# ATtiny87 device description
Architecture: AVR8; Family: tinyAVR
Registers are 8-bit, access not given, no defined reset value unless marked. A register's access mark holds for its fields unless they carry their own. Offsets are from the block's base; [hi:lo] are bit positions.

## TC1 (TC16 module) — Timer/Counter, 16-bit
Instances: TC1 0x00
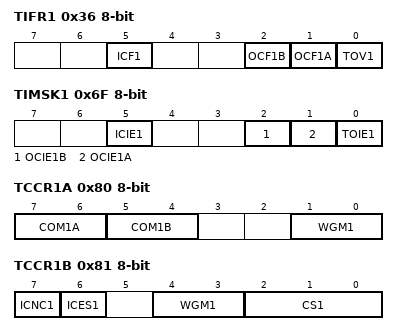
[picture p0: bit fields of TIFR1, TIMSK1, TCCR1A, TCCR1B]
0x36 TIFR1 — Timer/Counter1 Interrupt Flag register
  [5] ICF1 — Timer/Counter1 Input Capture Flag
  [2] OCF1B — Timer/Counter1 Output Compare B Match Flag
  [1] OCF1A — Timer/Counter1 Output Compare A Match Flag
  [0] TOV1 — Timer/Counter1 Overflow Flag
0x6F TIMSK1 — Timer/Counter1 Interrupt Mask Register
  [5] ICIE1 — Timer/Counter1 Input Capture Interrupt Enable
  [2] OCIE1B — Timer/Counter1 Output Compare B Match Interrupt Enable
  [1] OCIE1A — Timer/Counter1 Output Compare A Match Interrupt Enable
  [0] TOIE1 — Timer/Counter1 Overflow Interrupt Enable
0x80 TCCR1A — Timer/Counter1 Control Register A
  [7:6] COM1A — Compare Output Mode 1A, bits
  [5:4] COM1B — Compare Output Mode 1B, bits
  [1:0] WGM1 — Pulse Width Modulator Select Bits
0x81 TCCR1B — Timer/Counter1 Control Register B
  [7] ICNC1 — Input Capture 1 Noise Canceler
  [6] ICES1 — Input Capture 1 Edge Select
  [4:3] WGM1 (bit 2 of the value upward) — Waveform Generation Mode Bits
  [2:0] CS1 — Timer/Counter1 Clock Select bits
    0=NO_CLOCK_SOURCE_STOPPED; 1=RUNNING_NO_PRESCALING; 2=RUNNING_CLK_8; 3=RUNNING_CLK_64; 4=RUNNING_CLK_256; 5=RUNNING_CLK_1024; 6=RUNNING_EXTCLK_TN_FALLING_EDGE; 7=RUNNING_EXTCLK_TN_RISING_EDGE
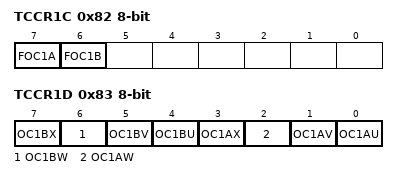
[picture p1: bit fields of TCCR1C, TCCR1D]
0x82 TCCR1C — Timer/Counter1 Control Register C
  [7] FOC1A — Timer/Counter1 Force Output Compare for Channel A
  [6] FOC1B — Timer/Counter1 Force Output Compare for Channel B
0x83 TCCR1D — Timer/Counter1 Control Register D
  [7] OC1BX — Timer/Counter1 Output Compare X-pin Enable for Channel B
  [6] OC1BW — Timer/Counter1 Output Compare W-pin Enable for Channel B
  [5] OC1BV — Timer/Counter1 Output Compare V-pin Enable for Channel B
  [4] OC1BU — Timer/Counter1 Output Compare U-pin Enable for Channel B
  [3] OC1AX — Timer/Counter1 Output Compare X-pin Enable for Channel A
  [2] OC1AW — Timer/Counter1 Output Compare W-pin Enable for Channel A
  [1] OC1AV — Timer/Counter1 Output Compare V-pin Enable for Channel A
  [0] OC1AU — Timer/Counter1 Output Compare U-pin Enable for Channel A
0x84 TCNT1 16-bit — Timer/Counter1 Bytes
0x86 ICR1 16-bit — Timer/Counter1 Input Capture Register Bytes
0x88 OCR1A 16-bit — Timer/Counter1 Output Compare Register A Bytes
0x8A OCR1B 16-bit — Timer/Counter1 Output Compare Register B Bytes

## WDT — Watchdog Timer
Instances: WDT 0x00
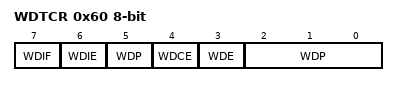
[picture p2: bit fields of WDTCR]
0x60 WDTCR — Watchdog Timer Control Register
  [7] WDIF — Watchdog Timeout Interrupt Flag
  [6] WDIE — Watchdog Timeout Interrupt Enable
  [4] WDCE — Watchdog Change Enable
  [3] WDE — Watch Dog Enable
  [5,2:0] WDP — Watchdog Timer Prescaler Bits
    0=OSCILLATOR_CYCLES_2K; 1=OSCILLATOR_CYCLES_4K; 2=OSCILLATOR_CYCLES_8K; 3=OSCILLATOR_CYCLES_16K; 4=OSCILLATOR_CYCLES_32K; 5=OSCILLATOR_CYCLES_64K; 6=OSCILLATOR_CYCLES_128K; 7=OSCILLATOR_CYCLES_256K; 8=OSCILLATOR_CYCLES_512K; 9=OSCILLATOR_CYCLES_1024K

## EEPROM
Instances: EEPROM 0x00
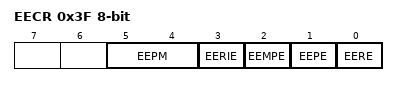
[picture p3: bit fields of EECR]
0x3F EECR — EEPROM Control Register
  [5:4] EEPM — EEPROM Programming Mode Bits
    0=ERASE_AND_WRITE_IN_ONE_OPERATION; 1=ERASE_ONLY; 2=WRITE_ONLY
  [3] EERIE — EEPROM Ready Interrupt Enable
  [2] EEMPE — EEPROM Master Write Enable
  [1] EEPE — EEPROM Write Enable
  [0] EERE — EEPROM Read Enable
0x40 EEDR — EEPROM Data Register
0x41 EEAR 16-bit bits used 8:0 — EEPROM Address Register Bytes

## SPI — Serial Peripheral Interface
Instances: SPI 0x00
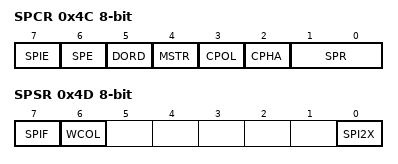
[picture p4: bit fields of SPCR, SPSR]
0x4C SPCR — SPI Control Register
  [7] SPIE — SPI Interrupt Enable
  [6] SPE — SPI Enable
  [5] DORD — Data Order
  [4] MSTR — Master/Slave Select
  [3] CPOL — Clock polarity
  [2] CPHA — Clock Phase
  [1:0] SPR — SPI Clock Rate Selects
    0=FOSC_4; 1=FOSC_16; 2=FOSC_64; 3=FOSC_128; 4=FOSC_2; 5=FOSC_8; 6=FOSC_32; 7=FOSC_64
0x4D SPSR — SPI Status Register
  [7] SPIF — SPI Interrupt Flag
  [6] WCOL — Write Collision Flag
  [0] SPI2X — Double SPI Speed Bit
0x4E SPDR — SPI Data Register
